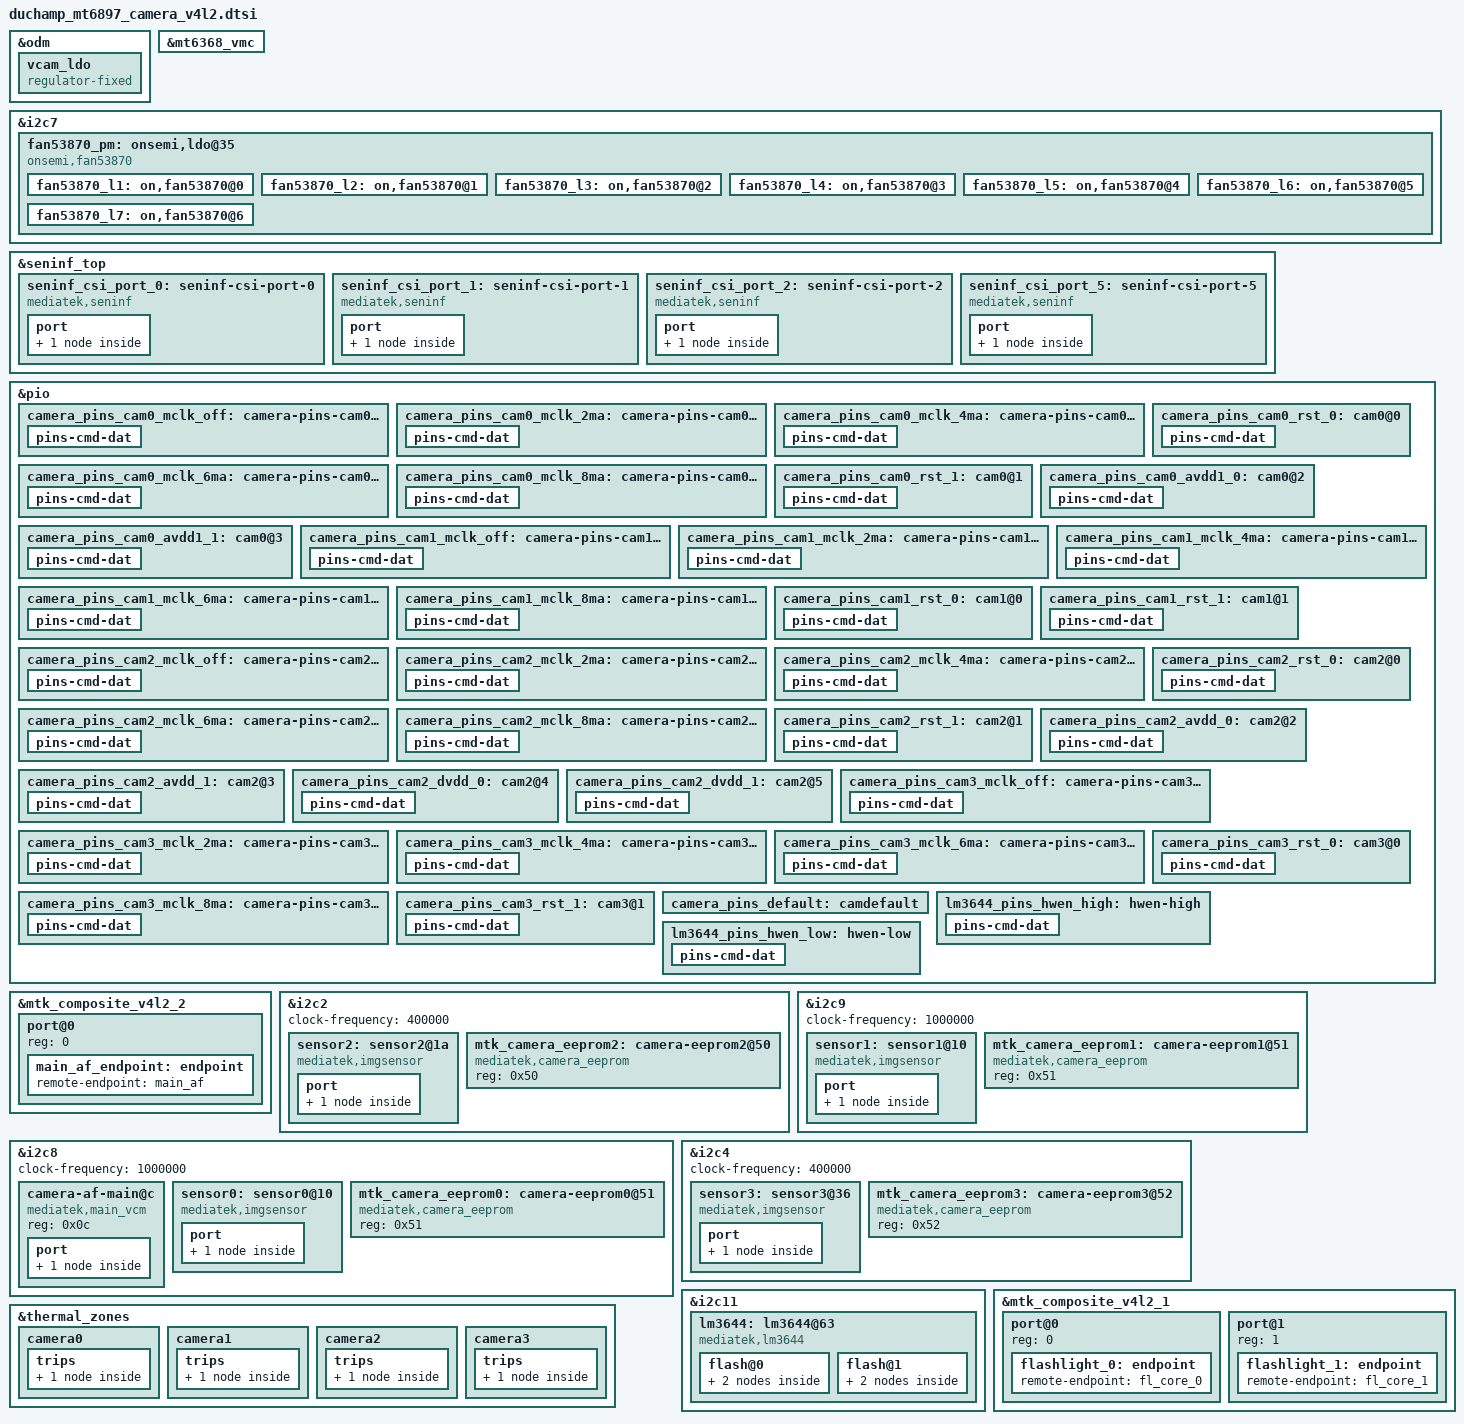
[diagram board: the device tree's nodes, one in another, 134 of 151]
// SPDX-License-Identifier: GPL-2.0
/* Copyright (c) 2020 MediaTek Inc. */
#include <dt-bindings/clock/mt6897-clk.h>

&odm {
	vcam_ldo:vcam_ldo {
		compatible = "regulator-fixed";
		regulator-name = "vcam_ldo";
		regulator-min-microvolt = <1800000>;
		regulator-max-microvolt = <1800000>;
		gpio = <&pio 121 0x0>;
		enable-active-high;
	};
};

&mt6368_vmc {
	regulator-compatible = "VMC";
	regulator-name = "mt6368_vmc";
	regulator-min-microvolt = <1790000>;
	regulator-max-microvolt = <1810000>;
	regulator-enable-ramp-delay = <680>;
	regulator-allowed-modes = <0 2>;
};

&i2c7 {
	#address-cells = <1>;
	#size-cells = <0>;

	fan53870_pm:onsemi,ldo@35 {
		compatible = "onsemi,fan53870";
		reg = <0x35>;/*slave address*/
		index = <0>;

		fan53870_l1:on,fan53870@0{
			offset = /bits/ 16 <0x0000>;
			regulator-name ="fan53870-l1";
			regulator-min-microvolt = <528000>;
			regulator-max-microvolt = <1504000>;
			min-dropout-voltage = <225000>;
			init-voltage = <1200000>;
			iout_ua = <650000>;
		};

		fan53870_l2:on,fan53870@1{
			offset = /bits/ 16 <0x0001>;
			regulator-name ="fan53870-l2";
			regulator-min-microvolt = <528000>;
			regulator-max-microvolt = <1504000>;
			min-dropout-voltage = <225000>;
			init-voltage = <1200000>;
			iout_ua = <650000>;
		};

		fan53870_l3:on,fan53870@2{
			offset = /bits/ 16 <0x0002>;
			regulator-name ="fan53870-l3";
			regulator-min-microvolt = <1504000>;
			regulator-max-microvolt = <3400000>;
			min-dropout-voltage = <200000>;
			init-voltage = <2800000>;
			iout_ua = <650000>;
		};

		fan53870_l4:on,fan53870@3{
			offset = /bits/ 16 <0x0003>;
			regulator-name ="fan53870-l4";
			regulator-min-microvolt = <1504000>;
			regulator-max-microvolt = <3400000>;
			min-dropout-voltage = <200000>;
			init-voltage = <2800000>;
			iout_ua = <650000>;
		};

		fan53870_l5:on,fan53870@4{
			offset = /bits/ 16 <0x0004>;
			regulator-name ="fan53870-l5";
			regulator-min-microvolt = <1504000>;
			regulator-max-microvolt = <3400000>;
			min-dropout-voltage = <300000>;
			init-voltage = <2700000>;
			iout_ua = <650000>;
		};

		fan53870_l6:on,fan53870@5{
			offset = /bits/ 16 <0x0005>;
			regulator-name ="fan53870-l6";
			regulator-min-microvolt = <1504000>;
			regulator-max-microvolt = <3400000>;
			min-dropout-voltage = <300000>;
			init-voltage = <2800000>;
			iout_ua = <650000>;
		};

		fan53870_l7:on,fan53870@6{
			offset = /bits/ 16 <0x0006>;
			regulator-name ="fan53870-l7";
			regulator-min-microvolt = <1504000>;
			regulator-max-microvolt = <3400000>;
			min-dropout-voltage = <300000>;
			init-voltage = <2800000>;
			iout_ua = <650000>;
		};
	};

};

&seninf_top {
		seninf_csi_port_0: seninf-csi-port-0 {
			compatible = "mediatek,seninf";
			csi-port = "0";
			dphy-settle-delay-dt = <17>;
			nvmem-cells = <&csi_efuse0>;
			nvmem-cell-names = "rg_csi";
			port {
				seninf_csi_port_0_in: endpoint {
					remote-endpoint = <&sensor1_out>;
				};
			};
		};

		seninf_csi_port_1: seninf-csi-port-1 {
			compatible = "mediatek,seninf";
			csi-port = "1";
			hs-trail-parameter = <0x20>;
			nvmem-cells = <&csi_efuse1>;
			nvmem-cell-names = "rg_csi";
			port {
				seninf_csi_port_1_in: endpoint {
					remote-endpoint = <&sensor3_out>;
				};
			};
		};

		seninf_csi_port_2: seninf-csi-port-2 {
			compatible = "mediatek,seninf";
			csi-port = "2";
			hs-trail-parameter = <0x20>;
			nvmem-cells = <&csi_efuse2>;
			nvmem-cell-names = "rg_csi";
			port {
				seninf_csi_port_2_in: endpoint {
					remote-endpoint = <&sensor0_out>;
				};
			};
		};
		seninf_csi_port_5: seninf-csi-port-5 {
			compatible = "mediatek,seninf";
			csi-port = "5";
			nvmem-cells = <&csi_efuse5>;
			nvmem-cell-names = "rg_csi";
			port {
				seninf_csi_port_5_in: endpoint {
					remote-endpoint = <&sensor2_out>;
				};
			};
		};
};

/* CAMERA GPIO standardization */
&pio {
	camera_pins_cam0_mclk_off: camera-pins-cam0-mclk-off {
		pins-cmd-dat {
			pinmux = <PINMUX_GPIO125__FUNC_GPIO125>;
			drive-strength = <1>;
		};
	};
	camera_pins_cam0_mclk_2ma: camera-pins-cam0-mclk-2ma {
		pins-cmd-dat {
			pinmux = <PINMUX_GPIO125__FUNC_CMMCLK2>;
			drive-strength = <0>;
		};
	};
	camera_pins_cam0_mclk_4ma: camera-pins-cam0-mclk-4ma {
		pins-cmd-dat {
			pinmux = <PINMUX_GPIO125__FUNC_CMMCLK2>;
			drive-strength = <1>;
		};
	};
	camera_pins_cam0_mclk_6ma: camera-pins-cam0-mclk-6ma {
		pins-cmd-dat {
			pinmux = <PINMUX_GPIO125__FUNC_CMMCLK2>;
			drive-strength = <2>;
		};
	};
	camera_pins_cam0_mclk_8ma: camera-pins-cam0-mclk-8ma {
		pins-cmd-dat {
			pinmux = <PINMUX_GPIO125__FUNC_CMMCLK2>;
			drive-strength = <3>;
		};
	};
	camera_pins_cam0_rst_0: cam0@0 {
		pins-cmd-dat {
			pinmux = <PINMUX_GPIO117__FUNC_GPIO117>;
			slew-rate = <1>;
			output-low;
		};
	};
	camera_pins_cam0_rst_1: cam0@1 {
		pins-cmd-dat {
			pinmux = <PINMUX_GPIO117__FUNC_GPIO117>;
			slew-rate = <1>;
			output-high;
		};
	};
	camera_pins_cam0_avdd1_0: cam0@2 {
		pins-cmd-dat {
			pinmux = <PINMUX_GPIO160__FUNC_GPIO160>;
			slew-rate = <1>;
			output-low;
		};
	};
	camera_pins_cam0_avdd1_1: cam0@3 {
		pins-cmd-dat {
			pinmux = <PINMUX_GPIO160__FUNC_GPIO160>;
			slew-rate = <1>;
			output-high;
		};
	};
	camera_pins_cam1_mclk_off: camera-pins-cam1-mclk-off {
		pins-cmd-dat {
			pinmux = <PINMUX_GPIO126__FUNC_GPIO126>;
			drive-strength = <1>;
		};
	};
	camera_pins_cam1_mclk_2ma: camera-pins-cam1-mclk-2ma {
		pins-cmd-dat {
			pinmux = <PINMUX_GPIO126__FUNC_CMMCLK3>;
			drive-strength = <0>;
		};
	};
	camera_pins_cam1_mclk_4ma: camera-pins-cam1-mclk-4ma {
		pins-cmd-dat {
			pinmux = <PINMUX_GPIO126__FUNC_CMMCLK3>;
			drive-strength = <1>;
		};
	};
	camera_pins_cam1_mclk_6ma: camera-pins-cam1-mclk-6ma {
		pins-cmd-dat {
			pinmux = <PINMUX_GPIO126__FUNC_CMMCLK3>;
			drive-strength = <2>;
		};
	};
	camera_pins_cam1_mclk_8ma: camera-pins-cam1-mclk-8ma {
		pins-cmd-dat {
			pinmux = <PINMUX_GPIO126__FUNC_CMMCLK3>;
			drive-strength = <3>;
		};
	};
	camera_pins_cam1_rst_0: cam1@0 {
		pins-cmd-dat {
			pinmux = <PINMUX_GPIO118__FUNC_GPIO118>;
			slew-rate = <1>;
			output-low;
		};
	};
	camera_pins_cam1_rst_1: cam1@1 {
		pins-cmd-dat {
			pinmux = <PINMUX_GPIO118__FUNC_GPIO118>;
			slew-rate = <1>;
			output-high;
		};
	};
	camera_pins_cam2_mclk_off: camera-pins-cam2-mclk-off {
		pins-cmd-dat {
			pinmux = <PINMUX_GPIO127__FUNC_GPIO127>;
			drive-strength = <1>;
		};
	};
	camera_pins_cam2_mclk_2ma: camera-pins-cam2-mclk-2ma {
		pins-cmd-dat {
			pinmux = <PINMUX_GPIO127__FUNC_CMMCLK4>;
			drive-strength = <0>;
		};
	};
	camera_pins_cam2_mclk_4ma: camera-pins-cam2-mclk-4ma {
		pins-cmd-dat {
			pinmux = <PINMUX_GPIO127__FUNC_CMMCLK4>;
			drive-strength = <1>;
		};
	};
	camera_pins_cam2_mclk_6ma: camera-pins-cam2-mclk-6ma {
		pins-cmd-dat {
			pinmux = <PINMUX_GPIO127__FUNC_CMMCLK4>;
			drive-strength = <2>;
		};
	};
	camera_pins_cam2_mclk_8ma: camera-pins-cam2-mclk-8ma {
		pins-cmd-dat {
			pinmux = <PINMUX_GPIO127__FUNC_CMMCLK4>;
			drive-strength = <3>;
		};
	};
	camera_pins_cam2_rst_0: cam2@0 {
		pins-cmd-dat {
			pinmux = <PINMUX_GPIO115__FUNC_GPIO115>;
			slew-rate = <1>;
			output-low;
		};
	};
	camera_pins_cam2_rst_1: cam2@1 {
		pins-cmd-dat {
			pinmux = <PINMUX_GPIO115__FUNC_GPIO115>;
			slew-rate = <1>;
			output-high;
		};
	};
	camera_pins_cam2_avdd_0: cam2@2 {
		pins-cmd-dat {
			pinmux = <PINMUX_GPIO80__FUNC_GPIO80>;
			slew-rate = <1>;
			output-low;
		};
	};

	camera_pins_cam2_avdd_1: cam2@3 {
		pins-cmd-dat {
			pinmux = <PINMUX_GPIO80__FUNC_GPIO80>;
			slew-rate = <1>;
			output-high;
		};
	};

	camera_pins_cam2_dvdd_0: cam2@4 {
		pins-cmd-dat {
			pinmux = <PINMUX_GPIO79__FUNC_GPIO79>;
			slew-rate = <1>;
			output-low;
		};
	};
	camera_pins_cam2_dvdd_1: cam2@5 {
		pins-cmd-dat {
			pinmux = <PINMUX_GPIO79__FUNC_GPIO79>;
			slew-rate = <1>;
			output-high;
		};
	};

	camera_pins_cam3_mclk_off: camera-pins-cam3-mclk-off {
		pins-cmd-dat {
			pinmux = <PINMUX_GPIO124__FUNC_GPIO124>;
			drive-strength = <1>;
		};
	};
	camera_pins_cam3_mclk_2ma: camera-pins-cam3-mclk-2ma {
		pins-cmd-dat {
			pinmux = <PINMUX_GPIO124__FUNC_CMMCLK1>;
			drive-strength = <0>;
		};
	};
	camera_pins_cam3_mclk_4ma: camera-pins-cam3-mclk-4ma {
		pins-cmd-dat {
			pinmux = <PINMUX_GPIO124__FUNC_CMMCLK1>;
			drive-strength = <1>;
		};
	};
	camera_pins_cam3_mclk_6ma: camera-pins-cam3-mclk-6ma {
		pins-cmd-dat {
			pinmux = <PINMUX_GPIO124__FUNC_CMMCLK1>;
			drive-strength = <2>;
		};
	};
	camera_pins_cam3_mclk_8ma: camera-pins-cam3-mclk-8ma {
		pins-cmd-dat {
			pinmux = <PINMUX_GPIO124__FUNC_CMMCLK1>;
			drive-strength = <3>;
		};
	};
	camera_pins_cam3_rst_0: cam3@0 {
		pins-cmd-dat {
			pinmux = <PINMUX_GPIO116__FUNC_GPIO116>;
			slew-rate = <1>;
			output-low;
		};
	};
	camera_pins_cam3_rst_1: cam3@1 {
		pins-cmd-dat {
			pinmux = <PINMUX_GPIO116__FUNC_GPIO116>;
			slew-rate = <1>;
			output-high;
		};
	};
	camera_pins_default: camdefault {
	};
};
/* CAMERA GPIO end */

&mtk_composite_v4l2_2 {
	#address-cells = <1>;
	#size-cells = <0>;
	port@0 {
		reg = <0>;
		main_af_endpoint: endpoint {
			remote-endpoint = <&main_af>;
		};
	};
};

&i2c2 {
	status = "okay";
	clock-frequency = <400000>;
	#address-cells = <1>;
	#size-cells = <0>;

	sensor2: sensor2@1a {
		compatible = "mediatek,imgsensor";
		sensor-names = "duchampov08d10ultra_mipi_raw";
		reg = <0x1a>;
		#thermal-sensor-cells = <0>;

		pinctrl-names = "mclk_off",
				"mclk_2mA",
				"mclk_4mA",
				"mclk_6mA",
				"mclk_8mA",
				"rst_low",
				"rst_high",
				"avdd_off",
				"avdd_on",
				"dvdd1_off",
				"dvdd1_on";
		pinctrl-0 = <&camera_pins_cam2_mclk_off>;
		pinctrl-1 = <&camera_pins_cam2_mclk_2ma>;
		pinctrl-2 = <&camera_pins_cam2_mclk_4ma>;
		pinctrl-3 = <&camera_pins_cam2_mclk_6ma>;
		pinctrl-4 = <&camera_pins_cam2_mclk_8ma>;
		pinctrl-5 = <&camera_pins_cam2_rst_0>;
		pinctrl-6 = <&camera_pins_cam2_rst_1>;
		pinctrl-7 = <&camera_pins_cam2_avdd_0>;
		pinctrl-8 = <&camera_pins_cam2_avdd_1>;
		pinctrl-9 = <&camera_pins_cam2_dvdd_0>;
		pinctrl-10 = <&camera_pins_cam2_dvdd_1>;

		dvdd-supply = <&vcam_ldo>;
		dovdd-supply = <&fan53870_l6>;

		clocks = <&topckgen_clk CLK_TOP_UNIVPLL_192M_D32>,
			<&topckgen_clk CLK_TOP_UNIVPLL_192M_D16>,
			<&topckgen_clk CLK_TOP_F26M_CK_D2>,
			<&topckgen_clk CLK_TOP_UNIVPLL_192M_D10>,
			<&topckgen_clk CLK_TOP_UNIVPLL_192M_D8>,
			<&topckgen_clk CLK_TOP_UNIVPLL_D6_D16>,
			<&topckgen_clk CLK_TOP_UNIVPLL_D6_D8>,
			<&topckgen_clk CLK_TOP_CAMTG5_SEL>;
		clock-names = "6", "12", "13", "19.2", "24", "26", "52", "mclk";

		status = "okay";

		port {
			sensor2_out: endpoint {
				remote-endpoint = <&seninf_csi_port_5_in>;
			};
		};
	};

	mtk_camera_eeprom2:camera-eeprom2@50 {
		compatible = "mediatek,camera_eeprom";
		reg = <0x50>;
		status = "okay";
	};
};

&i2c9 {
	status = "okay";
	clock-frequency = <1000000>;
	#address-cells = <1>;
	#size-cells = <0>;

	sensor1: sensor1@10 {
		compatible = "mediatek,imgsensor";
		sensor-names = "duchampov16a1qfront_mipi_raw";
		reg = <0x10>;
		#thermal-sensor-cells = <0>;

		pinctrl-names = "mclk_off",
				"mclk_2mA",
				"mclk_4mA",
				"mclk_6mA",
				"mclk_8mA",
				"rst_low",
				"rst_high";
		pinctrl-0 = <&camera_pins_cam1_mclk_off>;
		pinctrl-1 = <&camera_pins_cam1_mclk_2ma>;
		pinctrl-2 = <&camera_pins_cam1_mclk_4ma>;
		pinctrl-3 = <&camera_pins_cam1_mclk_6ma>;
		pinctrl-4 = <&camera_pins_cam1_mclk_8ma>;
		pinctrl-5 = <&camera_pins_cam1_rst_0>;
		pinctrl-6 = <&camera_pins_cam1_rst_1>;

		dvdd-supply = <&vcam_ldo>;
		avdd-supply = <&fan53870_l3>;
		dvdd1-supply = <&fan53870_l2>;
		dovdd-supply = <&fan53870_l6>;

		clocks = <&topckgen_clk CLK_TOP_UNIVPLL_192M_D32>,
			<&topckgen_clk CLK_TOP_UNIVPLL_192M_D16>,
			<&topckgen_clk CLK_TOP_F26M_CK_D2>,
			<&topckgen_clk CLK_TOP_UNIVPLL_192M_D10>,
			<&topckgen_clk CLK_TOP_UNIVPLL_192M_D8>,
			<&topckgen_clk CLK_TOP_UNIVPLL_D6_D16>,
			<&topckgen_clk CLK_TOP_UNIVPLL_D6_D8>,
			<&topckgen_clk CLK_TOP_CAMTG4_SEL>;
		clock-names = "6", "12", "13", "19.2", "24", "26", "52", "mclk";

		status = "okay";

		port {
			sensor1_out: endpoint {
				remote-endpoint = <&seninf_csi_port_0_in>;
			};
		};
	};

	mtk_camera_eeprom1:camera-eeprom1@51 {
		compatible = "mediatek,camera_eeprom";
		reg = <0x51>;
		status = "okay";
	};
};

&i2c8 {
	status = "okay";
	clock-frequency = <1000000>;
	#address-cells = <1>;
	#size-cells = <0>;

	camera-af-main@c {
		compatible = "mediatek,main_vcm";
		reg = <0x0c>;
		port {
			main_af: endpoint {
				remote-endpoint = <&main_af_endpoint>;
			};
		};
	};

	sensor0: sensor0@10 {
		compatible = "mediatek,imgsensor";
		sensor-names = "duchampov64b40wide_mipi_raw";
		reg = <0x10>;
		#thermal-sensor-cells = <0>;

		pinctrl-names = "mclk_off",
				"mclk_2mA",
				"mclk_4mA",
				"mclk_6mA",
				"mclk_8mA",
				"rst_low",
				"rst_high";
		pinctrl-0 = <&camera_pins_cam0_mclk_off>;
		pinctrl-1 = <&camera_pins_cam0_mclk_2ma>;
		pinctrl-2 = <&camera_pins_cam0_mclk_4ma>;
		pinctrl-3 = <&camera_pins_cam0_mclk_6ma>;
		pinctrl-4 = <&camera_pins_cam0_mclk_8ma>;
		pinctrl-5 = <&camera_pins_cam0_rst_0>;
		pinctrl-6 = <&camera_pins_cam0_rst_1>;
		dvdd-supply = <&vcam_ldo>;
		dvdd1-supply = <&fan53870_l1>;
		avdd-supply = <&fan53870_l4>;
		dovdd-supply = <&fan53870_l6>;
		afvdd-supply = <&fan53870_l5>;

		clocks = <&topckgen_clk CLK_TOP_UNIVPLL_192M_D32>,
			<&topckgen_clk CLK_TOP_UNIVPLL_192M_D16>,
			<&topckgen_clk CLK_TOP_F26M_CK_D2>,
			<&topckgen_clk CLK_TOP_UNIVPLL_192M_D10>,
			<&topckgen_clk CLK_TOP_UNIVPLL_192M_D8>,
			<&topckgen_clk CLK_TOP_UNIVPLL_D6_D16>,
			<&topckgen_clk CLK_TOP_UNIVPLL_D6_D8>,
			<&topckgen_clk CLK_TOP_CAMTG3_SEL>;
		clock-names = "6", "12", "13", "19.2", "24", "26", "52", "mclk";

		status = "okay";

		port {
			sensor0_out: endpoint {
				remote-endpoint = <&seninf_csi_port_2_in>;
			};
		};
	};

	mtk_camera_eeprom0:camera-eeprom0@51 {
		compatible = "mediatek,camera_eeprom";
		reg = <0x51>;
		status = "okay";
	};
};

&i2c4 {
	status = "okay";
	clock-frequency = <400000>;
	#address-cells = <1>;
	#size-cells = <0>;

	sensor3: sensor3@36 {
		compatible = "mediatek,imgsensor";
		sensor-names = "duchampsc202pcsmacro_mipi_raw";
		reg = <0x36>;
		#thermal-sensor-cells = <0>;
		pinctrl-names = "mclk_off",
				"mclk_2mA",
				"mclk_4mA",
				"mclk_6mA",
				"mclk_8mA",
				"rst_low",
				"rst_high";
		pinctrl-0 = <&camera_pins_cam3_mclk_off>;
		pinctrl-1 = <&camera_pins_cam3_mclk_2ma>;
		pinctrl-2 = <&camera_pins_cam3_mclk_4ma>;
		pinctrl-3 = <&camera_pins_cam3_mclk_6ma>;
		pinctrl-4 = <&camera_pins_cam3_mclk_8ma>;
		pinctrl-5 = <&camera_pins_cam3_rst_0>;
		pinctrl-6 = <&camera_pins_cam3_rst_1>;

		dvdd-supply = <&vcam_ldo>;
		avdd-supply = <&fan53870_l7>;
		dovdd-supply = <&mt6368_vmc>;

		clocks = <&topckgen_clk CLK_TOP_UNIVPLL_192M_D32>,
			<&topckgen_clk CLK_TOP_UNIVPLL_192M_D16>,
			<&topckgen_clk CLK_TOP_F26M_CK_D2>,
			<&topckgen_clk CLK_TOP_UNIVPLL_192M_D10>,
			<&topckgen_clk CLK_TOP_UNIVPLL_192M_D8>,
			<&topckgen_clk CLK_TOP_UNIVPLL_D6_D16>,
			<&topckgen_clk CLK_TOP_UNIVPLL_D6_D8>,
			<&topckgen_clk CLK_TOP_CAMTG2_SEL>;
		clock-names = "6", "12", "13", "19.2", "24", "26", "52", "mclk";

		status = "okay";

		port {
			sensor3_out: endpoint {
				remote-endpoint = <&seninf_csi_port_1_in>;
			};
		};
	};

	mtk_camera_eeprom3:camera-eeprom3@52 {
		compatible = "mediatek,camera_eeprom";
		reg = <0x52>;
		status = "okay";
	};
};

&i2c11 {
	#address-cells = <1>;
	#size-cells = <0>;
	lm3644:lm3644@63 {
		compatible = "mediatek,lm3644";
		#address-cells = <1>;
		#size-cells = <0>;
		reg = <0x63>;
		#cooling-cells = <2>;
		pinctrl-names = "hwen-high", "hwen-low";
		pinctrl-0 = <&lm3644_pins_hwen_high>;
		pinctrl-1 = <&lm3644_pins_hwen_low>;
		status = "okay";
		flash@0{
			reg = <0>;
			type = <0>;
			ct = <0>;
			part = <0>;
			port {
				fl_core_0: endpoint {
					remote-endpoint = <&flashlight_0>;
				};
			};
		};
		flash@1{
			reg = <1>;
			type = <0>;
			ct = <1>;
			part = <0>;
			port {
				fl_core_1: endpoint {
					remote-endpoint = <&flashlight_1>;
				};
			};
		};
	};
};

&pio {
	lm3644_pins_hwen_high: hwen-high {
		pins-cmd-dat {
			pinmux = <PINMUX_GPIO62__FUNC_GPIO62>;
			slew-rate = <1>;
			output-high;
		};
	};

	lm3644_pins_hwen_low: hwen-low {
		pins-cmd-dat {
			pinmux = <PINMUX_GPIO62__FUNC_GPIO62>;
			slew-rate = <1>;
			output-low;
		};
	};
};

&mtk_composite_v4l2_1 {
	#address-cells = <1>;
	#size-cells = <0>;
	port@0 {
		reg = <0>;
		flashlight_0: endpoint {
			remote-endpoint = <&fl_core_0>;
		};
	};
	port@1 {
		reg = <1>;
		flashlight_1: endpoint {
			remote-endpoint = <&fl_core_1>;
		};
	};
};


&thermal_zones {
	camera0: camera0 {
		polling-delay = <0>; /* milliseconds */
		polling-delay-passive = <0>; /* milliseconds */
		thermal-sensors = <&sensor0>;
		trips {
			camera0_crit: camera0-crit {
				temperature = <120000>;
				hysteresis = <2000>;
				type = "passive";
			};
		};
	};
	camera1: camera1 {
		polling-delay = <0>; /* milliseconds */
		polling-delay-passive = <0>; /* milliseconds */
		thermal-sensors = <&sensor1>;
		trips {
			camera1_crit: camera1-crit {
				temperature = <120000>;
				hysteresis = <2000>;
				type = "passive";
			};
		};
	};
	camera2: camera2 {
		polling-delay = <0>; /* milliseconds */
		polling-delay-passive = <0>; /* milliseconds */
		thermal-sensors = <&sensor2>;
		trips {
			camera2_crit: camera2-crit {
				temperature = <120000>;
				hysteresis = <2000>;
				type = "passive";
			};
		};
	};
	camera3: camera3 {
		polling-delay = <0>; /* milliseconds */
		polling-delay-passive = <0>; /* milliseconds */
		thermal-sensors = <&sensor3>;
		trips {
			camera3_crit: camera3-crit {
				temperature = <120000>;
				hysteresis = <2000>;
				type = "passive";
			};
		};
	};
};
